AUTOSAR XML (schema 00047)
package /Svc_CanTrcv
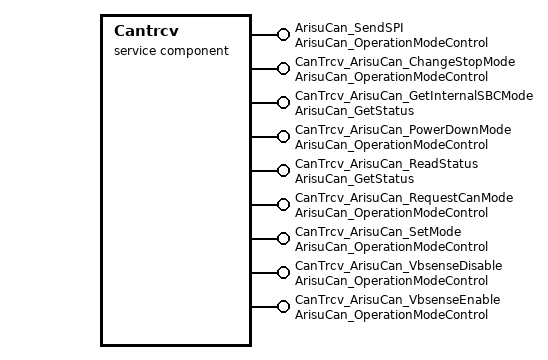
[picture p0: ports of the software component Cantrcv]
  service sw component type Cantrcv
    9 x provide port:
      ArisuCan_SendSPI: server-com-spec{operation=ArisuCan_SendSPI, queue-length=1}, provided-interface=ArisuCan_OperationModeControl
      CanTrcv_ArisuCan_ChangeStopMode: server-com-spec{operation=CanTrcv_ArisuCan_ChangeStopMode, queue-length=1}, provided-interface=ArisuCan_OperationModeControl
      CanTrcv_ArisuCan_GetInternalSBCMode: server-com-spec{operation=CanTrcv_ArisuCan_GetInternalSBCMode, queue-length=1}, provided-interface=ArisuCan_GetStatus
      CanTrcv_ArisuCan_PowerDownMode: server-com-spec{operation=CanTrcv_ArisuCan_PowerDownMode, queue-length=1}, provided-interface=ArisuCan_OperationModeControl
      CanTrcv_ArisuCan_ReadStatus: server-com-spec{operation=CanTrcv_ArisuCan_ReadStatus, queue-length=1}, provided-interface=ArisuCan_GetStatus
      CanTrcv_ArisuCan_RequestCanMode: server-com-spec{operation=CanTrcv_ArisuCan_RequestCanMode, queue-length=1}, provided-interface=ArisuCan_OperationModeControl
      CanTrcv_ArisuCan_SetMode: server-com-spec{operation=CanTrcv_ArisuCan_SetMode, queue-length=1}, provided-interface=ArisuCan_OperationModeControl
      CanTrcv_ArisuCan_VbsenseDisable: server-com-spec{operation=CanTrcv_ArisuCan_VbsenseDisable, queue-length=1}, provided-interface=ArisuCan_OperationModeControl
      CanTrcv_ArisuCan_VbsenseEnable: server-com-spec{operation=CanTrcv_ArisuCan_VbsenseEnable, queue-length=1}, provided-interface=ArisuCan_OperationModeControl
    behavior SwcInternalBehavior_CanTrcv: swc-exclusive-area-policy{api-principle=COMMON, exclusive-area=CanTrcv_INTERRUPT_PROTECTION_AREA}, included-data-type-set=data-type=[ArisuCan_SBCModeType, CanTrcv_ArisuCanType, CanTrcv_HwType]
      exclusive area CanTrcv_INTERRUPT_PROTECTION_AREA
      9 x operation invoked event:
        OIE_ArisuCan_SendSPI: start-on-event=ArisuCan_SendSPI, operation=ArisuCan_SendSPI.ArisuCan_SendSPI
        OIE_CanTrcv_ArisuCan_ChangeStopMode: start-on-event=CanTrcv_ArisuCan_ChangeStopMode, operation=CanTrcv_ArisuCan_ChangeStopMode.CanTrcv_ArisuCan_ChangeStopMode
        OIE_CanTrcv_ArisuCan_GetInternalSBCMode: start-on-event=CanTrcv_ArisuCan_GetInternalSBCMode, operation=CanTrcv_ArisuCan_GetInternalSBCMode.CanTrcv_ArisuCan_GetInternalSBCMode
        OIE_CanTrcv_ArisuCan_PowerDownMode: start-on-event=CanTrcv_ArisuCan_PowerDownMode, operation=CanTrcv_ArisuCan_PowerDownMode.CanTrcv_ArisuCan_PowerDownMode
        OIE_CanTrcv_ArisuCan_ReadStatus: start-on-event=CanTrcv_ArisuCan_ReadStatus, operation=CanTrcv_ArisuCan_ReadStatus.CanTrcv_ArisuCan_ReadStatus
        OIE_CanTrcv_ArisuCan_RequestCanMode: start-on-event=CanTrcv_ArisuCan_RequestCanMode, operation=CanTrcv_ArisuCan_RequestCanMode.CanTrcv_ArisuCan_RequestCanMode
        OIE_CanTrcv_ArisuCan_SetMode: start-on-event=CanTrcv_ArisuCan_SetMode, operation=CanTrcv_ArisuCan_SetMode.CanTrcv_ArisuCan_SetMode
        OIE_CanTrcv_ArisuCan_VbsenseDisable: start-on-event=CanTrcv_ArisuCan_VbsenseDisable, operation=CanTrcv_ArisuCan_VbsenseDisable.CanTrcv_ArisuCan_VbsenseDisable
        OIE_CanTrcv_ArisuCan_VbsenseEnable: start-on-event=CanTrcv_ArisuCan_VbsenseEnable, operation=CanTrcv_ArisuCan_VbsenseEnable.CanTrcv_ArisuCan_VbsenseEnable
      9 x runnable, all with can-be-invoked-concurrently=true:
        ArisuCan_SendSPI: can-enter-exclusive-area=CanTrcv_INTERRUPT_PROTECTION_AREA, reentrancy-level=NON-REENTRANT
        CanTrcv_ArisuCan_ChangeStopMode: can-enter-exclusive-area=CanTrcv_INTERRUPT_PROTECTION_AREA, reentrancy-level=NON-REENTRANT
        CanTrcv_ArisuCan_GetInternalSBCMode: reentrancy-level=SINGLE-CORE-REENTRANT
        CanTrcv_ArisuCan_PowerDownMode: can-enter-exclusive-area=CanTrcv_INTERRUPT_PROTECTION_AREA, reentrancy-level=NON-REENTRANT
        CanTrcv_ArisuCan_ReadStatus: can-enter-exclusive-area=CanTrcv_INTERRUPT_PROTECTION_AREA, reentrancy-level=NON-REENTRANT
        CanTrcv_ArisuCan_RequestCanMode: can-enter-exclusive-area=CanTrcv_INTERRUPT_PROTECTION_AREA, reentrancy-level=NON-REENTRANT
        CanTrcv_ArisuCan_SetMode: can-enter-exclusive-area=CanTrcv_INTERRUPT_PROTECTION_AREA, reentrancy-level=NON-REENTRANT
        CanTrcv_ArisuCan_VbsenseDisable: can-enter-exclusive-area=CanTrcv_INTERRUPT_PROTECTION_AREA, reentrancy-level=NON-REENTRANT
        CanTrcv_ArisuCan_VbsenseEnable: can-enter-exclusive-area=CanTrcv_INTERRUPT_PROTECTION_AREA, reentrancy-level=NON-REENTRANT
  swc implementation SwcImplementation_CanTrcv: programming-language=C, sw-version=1.0.11, swc-bsw-mapping=SwcBswMapping_CanTrcv, vendor-id=76, behavior=SwcInternalBehavior_CanTrcv
package /Svc_CanTrcv/ClientServerInterfaces
  client server interface ArisuCan_GetStatus: is-service=true
    operation CanTrcv_ArisuCan_GetInternalSBCMode
    operation CanTrcv_ArisuCan_ReadStatus: possible-error=[ArisuCan_GetStatus/E_NOT_OK, ArisuCan_GetStatus/E_OK]
      arg address: type=CanTrcv_ArisuCanType, direction=IN
      arg data: type=CanTrcv_ArisuCanType, direction=INOUT
    error E_NOT_OK: error-code=1
    error E_OK: error-code=0
  client server interface ArisuCan_OperationModeControl: is-service=true
    7 x operation:
      ArisuCan_SendSPI: possible-error=[ArisuCan_OperationModeControl/E_NOT_OK, ArisuCan_OperationModeControl/E_OK]
        arg SpiSrcData: direction=IN
        arg SpiDestData: direction=INOUT
      CanTrcv_ArisuCan_ChangeStopMode: possible-error=[ArisuCan_OperationModeControl/E_NOT_OK, ArisuCan_OperationModeControl/E_OK]
      CanTrcv_ArisuCan_PowerDownMode: possible-error=[ArisuCan_OperationModeControl/E_NOT_OK, ArisuCan_OperationModeControl/E_OK]
      CanTrcv_ArisuCan_RequestCanMode
        arg canTrcv: type=CanTrcv_HwType, direction=IN
        arg mode: type=ArisuCan_SBCModeType, direction=IN
      CanTrcv_ArisuCan_SetMode: possible-error=[ArisuCan_OperationModeControl/E_NOT_OK, ArisuCan_OperationModeControl/E_OK]
        arg mode: type=ArisuCan_SBCModeType, direction=IN
      CanTrcv_ArisuCan_VbsenseDisable: possible-error=[ArisuCan_OperationModeControl/E_NOT_OK, ArisuCan_OperationModeControl/E_OK]
      CanTrcv_ArisuCan_VbsenseEnable: possible-error=[ArisuCan_OperationModeControl/E_NOT_OK, ArisuCan_OperationModeControl/E_OK]
    error E_NOT_OK: error-code=1
    error E_OK: error-code=0
package /Svc_CanTrcv/ImplementationDataTypes
  impl type ArisuCan_SBCModeType: category=VALUE, compu {0, 1, 2, 3, 4, 5}, range raw 0..5, raw 0..5
  impl type CanTrcv_ArisuCanType: category=TYPE_REFERENCE, base-type=uint16
  impl type CanTrcv_HwType: category=VALUE, compu {0, 1, 2, 3, 4, 5, 6, 7, 8, 9, 10, 11, 12, 13, 14, 15, 16, 17, 18, 19, 20, 21, 22, 23, 24, 25, 26, 27, 28, 29, 30, 31, 32, 33, 34, 35}, range raw 0..36, raw 0..35
